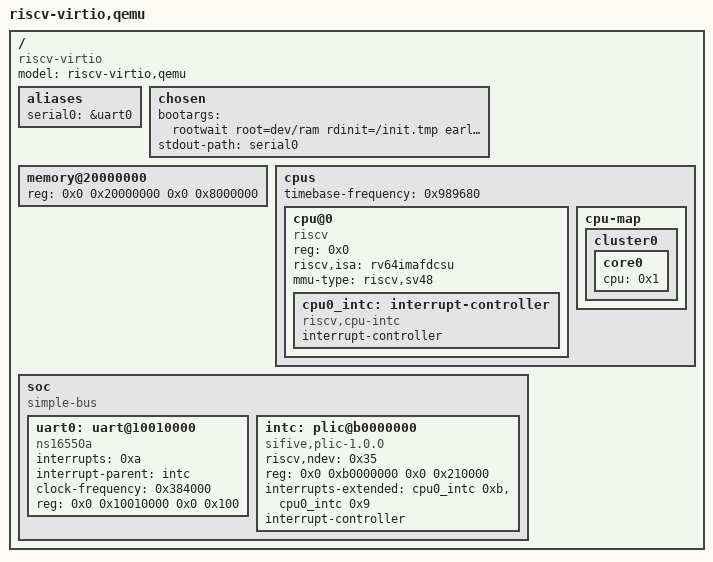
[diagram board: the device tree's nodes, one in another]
/dts-v1/;

/ {
	#address-cells = <0x2>;
	#size-cells = <0x2>;
	compatible = "riscv-virtio";
	model = "riscv-virtio,qemu";

	aliases {
		serial0 = &uart0;
	};

	chosen {
		bootargs = "rootwait root=dev/ram rdinit=/init.tmp earlycon=sbi console=ttyS0";
		stdout-path = "serial0";
	};

	memory@20000000 {
		device_type = "memory";
		reg = <0x0 0x20000000 0x0 0x8000000>;
	};

	cpus {
		#address-cells = <0x1>;
		#size-cells = <0x0>;
		timebase-frequency = <0x989680>;

		cpu@0 {
			device_type = "cpu";
			reg = <0x0>;
			status = "okay";
			compatible = "riscv";
			riscv,isa = "rv64imafdcsu";
			mmu-type = "riscv,sv48";

			cpu0_intc:interrupt-controller {
				#interrupt-cells = <0x1>;
				interrupt-controller;
				compatible = "riscv,cpu-intc";
			};
		};

		cpu-map {

			cluster0 {

				core0 {
					cpu = <0x1>;
				};
			};
		};
	};

	soc {
		#address-cells = <0x2>;
		#size-cells = <0x2>;
		compatible = "simple-bus";
		ranges;

		uart0:uart@10010000 {
			interrupts = <0xa>;
			interrupt-parent = <&intc>;
			clock-frequency = <0x384000>;
			reg = <0x0 0x10010000 0x0 0x100>;
			compatible = "ns16550a";
		};

		intc:plic@b0000000 {
			riscv,ndev = <0x35>;
			reg = <0x0 0xb0000000 0x0 0x210000>;
			interrupts-extended = <&cpu0_intc 0xb &cpu0_intc 0x9>;
			interrupt-controller;
			compatible = "sifive,plic-1.0.0", "riscv,plic0";
			#interrupt-cells = <0x1>;
			#address-cells = <0x0>;
		};
	};
};
